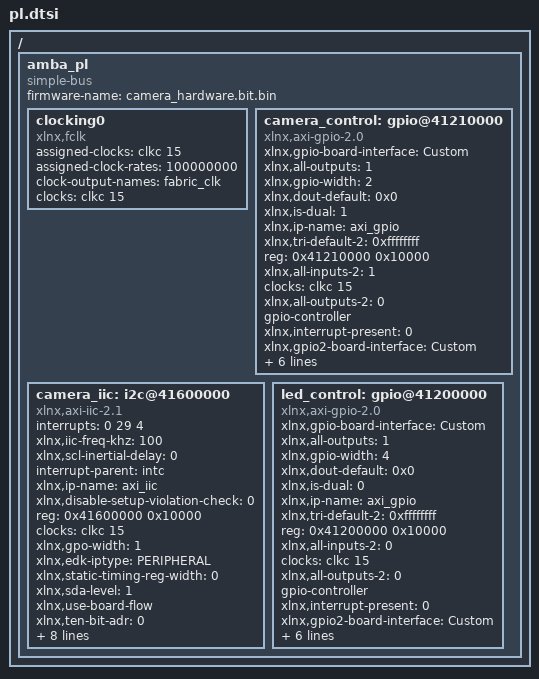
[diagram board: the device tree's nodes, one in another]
/ {
	amba_pl: amba_pl {
		ranges;
		compatible = "simple-bus";
		#address-cells = <1>;
		#size-cells = <1>;
		firmware-name = "camera_hardware.bit.bin";
		clocking0: clocking0 {
			compatible = "xlnx,fclk";
			assigned-clocks = <&clkc 15>;
			assigned-clock-rates = <100000000>;
			#clock-cells = <0>;
			clock-output-names = "fabric_clk";
			clocks = <&clkc 15>;
		};
		camera_control: gpio@41210000 {
			xlnx,gpio-board-interface = "Custom";
			compatible = "xlnx,axi-gpio-2.0" , "xlnx,xps-gpio-1.00.a";
			xlnx,all-outputs = <1>;
			#gpio-cells = <2>;
			xlnx,gpio-width = <2>;
			xlnx,dout-default = <0x0>;
			xlnx,is-dual = <1>;
			xlnx,ip-name = "axi_gpio";
			xlnx,tri-default-2 = <0xffffffff>;
			reg = <0x41210000 0x10000>;
			xlnx,all-inputs-2 = <1>;
			clocks = <&clkc 15>;
			xlnx,all-outputs-2 = <0>;
			gpio-controller;
			xlnx,interrupt-present = <0>;
			xlnx,gpio2-board-interface = "Custom";
			xlnx,edk-iptype = "PERIPHERAL";
			xlnx,dout-default-2 = <0x0>;
			status = "okay";
			xlnx,gpio2-width = <1>;
			clock-names = "s_axi_aclk";
			xlnx,tri-default = <0xffffffff>;
			xlnx,name = "camera_control";
			xlnx,all-inputs = <0>;
		};
		camera_iic: i2c@41600000 {
			interrupts = < 0 29 4 >;
			xlnx,iic-freq-khz = <100>;
			compatible = "xlnx,axi-iic-2.1" , "xlnx,xps-iic-2.00.a";
			xlnx,scl-inertial-delay = <0>;
			interrupt-parent = <&intc>;
			xlnx,ip-name = "axi_iic";
			xlnx,disable-setup-violation-check = <0>;
			reg = <0x41600000 0x10000>;
			clocks = <&clkc 15>;
			xlnx,gpo-width = <1>;
			xlnx,edk-iptype = "PERIPHERAL";
			xlnx,static-timing-reg-width = <0>;
			xlnx,sda-level = <1>;
			status = "okay";
			clock-names = "s_axi_aclk";
			xlnx,use-board-flow;
			xlnx,ten-bit-adr = <0>;
			xlnx,default-value = <0x0>;
			interrupt-names = "iic2intc_irpt";
			xlnx,iic-board-interface = "Custom";
			xlnx,timing-reg-width = <32>;
			xlnx,iic-freq = <100000>;
			xlnx,smbus-pmbus-host = <0>;
			xlnx,name = "camera_iic";
			xlnx,axi-aclk-freq-mhz = <0x5f5e095>;
			xlnx,sda-inertial-delay = <0>;
		};
		led_control: gpio@41200000 {
			xlnx,gpio-board-interface = "Custom";
			compatible = "xlnx,axi-gpio-2.0" , "xlnx,xps-gpio-1.00.a";
			xlnx,all-outputs = <1>;
			#gpio-cells = <2>;
			xlnx,gpio-width = <4>;
			xlnx,dout-default = <0x0>;
			xlnx,is-dual = <0>;
			xlnx,ip-name = "axi_gpio";
			xlnx,tri-default-2 = <0xffffffff>;
			reg = <0x41200000 0x10000>;
			xlnx,all-inputs-2 = <0>;
			clocks = <&clkc 15>;
			xlnx,all-outputs-2 = <0>;
			gpio-controller;
			xlnx,interrupt-present = <0>;
			xlnx,gpio2-board-interface = "Custom";
			xlnx,edk-iptype = "PERIPHERAL";
			xlnx,dout-default-2 = <0x0>;
			status = "okay";
			xlnx,gpio2-width = <32>;
			clock-names = "s_axi_aclk";
			xlnx,tri-default = <0xffffffff>;
			xlnx,name = "led_control";
			xlnx,all-inputs = <0>;
		};
	};
};
